# COREAON_PRM register map
Vendor: Texas Instruments
Peripheral module from a debugger description file (folder am571x).
Registers are 32-bit, access per field, reset 0x1 unless marked. A register's access mark holds for its fields unless they carry their own. Offsets are as the file gives them; lines under a group give offsets from that group; [hi:lo] are bit positions; {n}, {i} and the like mark numbered series; 'fields as' and 'values as' point back to an identical list; <NAME> marks a mode.

## COREAON_PRM
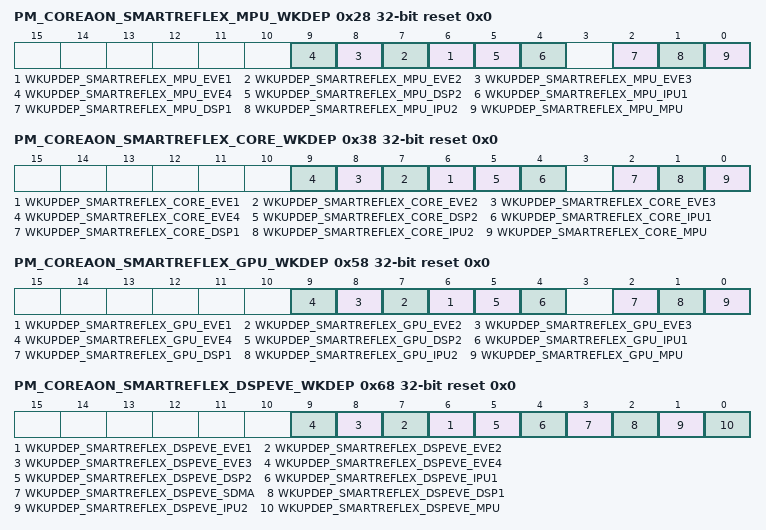
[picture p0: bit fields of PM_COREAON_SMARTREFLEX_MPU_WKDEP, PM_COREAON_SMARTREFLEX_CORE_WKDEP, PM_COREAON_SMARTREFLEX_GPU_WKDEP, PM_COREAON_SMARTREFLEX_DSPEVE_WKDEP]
0x28 PM_COREAON_SMARTREFLEX_MPU_WKDEP reset 0x0 — This register controls wakeup dependency based on SMARTREFLEX_MPU service requests.
  [all] fields
    0=DISABLED (Dependency is disabled); 1=ENABLED (Dependency is enabled)
  [n+5] WKUPDEP_SMARTREFLEX_MPU_EVE{n} rw (n=1..4) — Wakeup dependency from SMARTREFLEX_MPU module (SWakeup signal) towards EVE{n} + L3_MAIN1 + L4PER1 + L4PER2 + L4PER3 domains
  [5] WKUPDEP_SMARTREFLEX_MPU_DSP2 rw — Wakeup dependency from SMARTREFLEX_MPU module (SWakeup signal) towards DSP2 + L3_MAIN1 + L4PER1 + L4PER2 + L4PER3 domains
  [4] WKUPDEP_SMARTREFLEX_MPU_IPU1 rw — Wakeup dependency from SMARTREFLEX_MPU module (SWakeup signal) towards IPU1 + L3_MAIN1 + L4PER1 + L4PER2 + L4PER3 domains
  [2] WKUPDEP_SMARTREFLEX_MPU_DSP1 rw — Wakeup dependency from SMARTREFLEX_MPU module (SWakeup signal) towards DSP + L3MAIN1 + L4PER1 + L4PER2 + L4PER3 domains
  [1] WKUPDEP_SMARTREFLEX_MPU_IPU2 rw — Wakeup dependency from SMARTREFLEX_MPU module (SWakeup signal) towards IPU2 + L3_MAIN1 + L4PER1 + L4PER2 + L4PER3 domains
  [0] WKUPDEP_SMARTREFLEX_MPU_MPU rw — Wakeup dependency from SMARTREFLEX_MPU module (SWakeup signal) towards MPU + L3_MAIN1 + L4PER1 + L4PER2 + L4PER3 domains
0x2C RM_COREAON_SMARTREFLEX_MPU_CONTEXT — This register contains dedicated SMARTREFLEX_MPU context statuses. [warm reset insensitive]
  [0] LOSTCONTEXT_DFF rw — Specify if DFF-based context has been lost due to a previous power transition or other reset source. (set upon assertion of COREAON_RST signal)
    0=MAINTAINED (Context has been maintained); 1=LOST (Context has been lost)
0x38 PM_COREAON_SMARTREFLEX_CORE_WKDEP reset 0x0 — This register controls wakeup dependency based on SMARTREFLEX_CORE service requests.
  [all] fields
    values as the fields of PM_COREAON_SMARTREFLEX_MPU_WKDEP
  [n+5] WKUPDEP_SMARTREFLEX_CORE_EVE{n} rw (n=1..4) — Wakeup dependency from SMARTREFLEX_CORE module (SWakeup signal) towards EVE{n} + L3_MAIN1 + L4PER1 + L4PER2 + L4PER3 domains
  [5] WKUPDEP_SMARTREFLEX_CORE_DSP2 rw — Wakeup dependency from SMARTREFLEX_CORE module (SWakeup signal) towards DSP2 + L3_MAIN1 + L4PER1 + L4PER2 + L4PER3 domains
  [4] WKUPDEP_SMARTREFLEX_CORE_IPU1 rw — Wakeup dependency from SMARTREFLEX_CORE module (SWakeup signal) towards IPU1 + L3_MAIN1 + L4PER1 + L4PER2 + L4PER3 domains
  [2] WKUPDEP_SMARTREFLEX_CORE_DSP1 rw — Wakeup dependency from SMARTREFLEX_CORE module (SWakeup signal) towards DSP + L3MAIN1 + L4PER1 + L4PER2 + L4PER3 domains
  [1] WKUPDEP_SMARTREFLEX_CORE_IPU2 rw — Wakeup dependency from SMARTREFLEX_CORE module (SWakeup signal) towards IPU2 + L3_MAIN1 + L4PER1 + L4PER2 + L4PER3 domains
  [0] WKUPDEP_SMARTREFLEX_CORE_MPU rw — Wakeup dependency from SMARTREFLEX_CORE module (SWakeup signal) towards MPU + L3_MAIN1 + L4PER1 + L4PER2 + L4PER3 domains
0x3C RM_COREAON_SMARTREFLEX_CORE_CONTEXT — This register contains dedicated SMARTREFLEX_CORE context statuses. [warm reset insensitive]
  fields as RM_COREAON_SMARTREFLEX_MPU_CONTEXT
0x58 PM_COREAON_SMARTREFLEX_GPU_WKDEP reset 0x0 — This register controls wakeup dependency based on SMARTREFLEX_GPU service requests.
  [all] fields
    values as the fields of PM_COREAON_SMARTREFLEX_MPU_WKDEP
  [n+5] WKUPDEP_SMARTREFLEX_GPU_EVE{n} rw (n=1..4) — Wakeup dependency from SMARTREFLEX_GPU module (SWakeup signal) towards EVE{n} + L3_MAIN1 + L4PER1 + L4PER2 + L4PER3 domains
  [5] WKUPDEP_SMARTREFLEX_GPU_DSP2 rw — Wakeup dependency from SMARTREFLEX_GPU module (SWakeup signal) towards DSP2 + L3_MAIN1 + L4PER1 + L4PER2 + L4PER3 domains
  [4] WKUPDEP_SMARTREFLEX_GPU_IPU1 rw — Wakeup dependency from SMARTREFLEX_GPU module (SWakeup signal) towards IPU1 + L3_MAIN1 + L4PER1 + L4PER2 + L4PER3 domains
  [2] WKUPDEP_SMARTREFLEX_GPU_DSP1 rw — Wakeup dependency from SMARTREFLEX_GPU module (SWakeup signal) towards DSP + L3MAIN1 + L4PER1 + L4PER2 + L4PER3 domains
  [1] WKUPDEP_SMARTREFLEX_GPU_IPU2 rw — Wakeup dependency from SMARTREFLEX_GPU module (SWakeup signal) towards IPU2 + L3_MAIN1 + L4PER1 + L4PER2 + L4PER3 domains
  [0] WKUPDEP_SMARTREFLEX_GPU_MPU rw — Wakeup dependency from SMARTREFLEX_GPU module (SWakeup signal) towards MPU + L3_MAIN1 + L4PER1 + L4PER2 + L4PER3 domains
0x5C RM_COREAON_SMARTREFLEX_GPU_CONTEXT — This register contains dedicated SMARTREFLEX_GPU context statuses. [warm reset insensitive]
  fields as RM_COREAON_SMARTREFLEX_MPU_CONTEXT
0x68 PM_COREAON_SMARTREFLEX_DSPEVE_WKDEP reset 0x0 — This register controls wakeup dependency based on SMARTREFLEX_DSPEVE service requests.
  [all] fields
    values as the fields of PM_COREAON_SMARTREFLEX_MPU_WKDEP
  [n+5] WKUPDEP_SMARTREFLEX_DSPEVE_EVE{n} rw (n=1..4) — Wakeup dependency from SMARTREFLEX_DSPEVE module (SWakeup signal) towards EVE{n} + L3_MAIN1 + L4PER1 + L4PER2 + L4PER3 domains
  [5] WKUPDEP_SMARTREFLEX_DSPEVE_DSP2 rw — Wakeup dependency from SMARTREFLEX_DSPEVE module (SWakeup signal) towards DSP2 + L3_MAIN1 + L4PER1 + L4PER2 + L4PER3 domains
  [4] WKUPDEP_SMARTREFLEX_DSPEVE_IPU1 rw — Wakeup dependency from SMARTREFLEX_DSPEVE module (SWakeup signal) towards IPU1 + L3_MAIN1 + L4PER1 + L4PER2 + L4PER3 domains
  [3] WKUPDEP_SMARTREFLEX_DSPEVE_SDMA rw — Wakeup dependency from SMARTREFLEX_DSPEVE module (SWakeup signal) towards SDMA + L3MAIN1 + L4PER1 + L4PER2 + L4PER3 domains
  [2] WKUPDEP_SMARTREFLEX_DSPEVE_DSP1 rw — Wakeup dependency from SMARTREFLEX_GPU module (SWakeup signal) towards DSP + L3MAIN1 + L4PER1 + L4PER2 + L4PER3 domains
  [1] WKUPDEP_SMARTREFLEX_DSPEVE_IPU2 rw — Wakeup dependency from SMARTREFLEX_DSPEVE module (SWakeup signal) towards IPU2 + L3_MAIN1 + L4PER1 + L4PER2 + L4PER3 domains
  [0] WKUPDEP_SMARTREFLEX_DSPEVE_MPU rw — Wakeup dependency from SMARTREFLEX_DSPEVE module (SWakeup signal) towards MPU + L3_MAIN1 + L4PER1 + L4PER2 + L4PER3 domains
0x6C RM_COREAON_SMARTREFLEX_DSPEVE_CONTEXT — This register contains dedicated SMARTREFLEX_DSPEVE context statuses. [warm reset insensitive]
  fields as RM_COREAON_SMARTREFLEX_MPU_CONTEXT
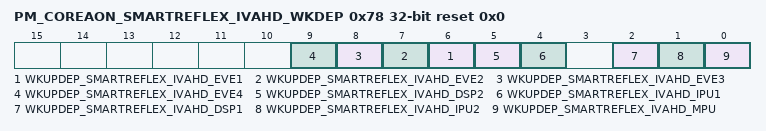
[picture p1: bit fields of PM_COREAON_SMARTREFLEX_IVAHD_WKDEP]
0x78 PM_COREAON_SMARTREFLEX_IVAHD_WKDEP reset 0x0 — This register controls wakeup dependency based on SMARTREFLEX_IVAHD service requests.
  [all] fields
    values as the fields of PM_COREAON_SMARTREFLEX_MPU_WKDEP
  [n+5] WKUPDEP_SMARTREFLEX_IVAHD_EVE{n} rw (n=1..4) — Wakeup dependency from SMARTREFLEX_IVAHD module (SWakeup signal) towards EVE{n} + L3_MAIN1 + L4PER1 + L4PER2 + L4PER3 domains
  [5] WKUPDEP_SMARTREFLEX_IVAHD_DSP2 rw — Wakeup dependency from SMARTREFLEX_IVAHD module (SWakeup signal) towards DSP2 + L3_MAIN1 + L4PER1 + L4PER2 + L4PER3 domains
  [4] WKUPDEP_SMARTREFLEX_IVAHD_IPU1 rw — Wakeup dependency from SMARTREFLEX_IVAHD module (SWakeup signal) towards IPU1 + L3_MAIN1 + L4PER1 + L4PER2 + L4PER3 domains
  [2] WKUPDEP_SMARTREFLEX_IVAHD_DSP1 rw — Wakeup dependency from SMARTREFLEX_IVAHD module (SWakeup signal) towards DSP + L3MAIN1 + L4PER1 + L4PER2 + L4PER3 domains
  [1] WKUPDEP_SMARTREFLEX_IVAHD_IPU2 rw — Wakeup dependency from SMARTREFLEX_IVAHD module (SWakeup signal) towards IPU2 + L3_MAIN1 + L4PER1 + L4PER2 + L4PER3 domains
  [0] WKUPDEP_SMARTREFLEX_IVAHD_MPU rw — Wakeup dependency from SMARTREFLEX_IVAHD module (SWakeup signal) towards MPU + L3_MAIN1 + L4PER1 + L4PER2 + L4PER3 domains
0x7C RM_COREAON_SMARTREFLEX_IVAHD_CONTEXT — This register contains dedicated SMARTREFLEX_IVA context statuses. [warm reset insensitive]
  fields as RM_COREAON_SMARTREFLEX_MPU_CONTEXT
0xAC RM_COREAON_DUMMY_MODULE1_CONTEXT — This register contains dedicated DUMMY MODULE1 context statuses. [warm reset insensitive]
  fields as RM_COREAON_SMARTREFLEX_MPU_CONTEXT
0xBC RM_COREAON_DUMMY_MODULE2_CONTEXT — This register contains dedicated DUMMY MODULE2 context statuses. [warm reset insensitive]
  fields as RM_COREAON_SMARTREFLEX_MPU_CONTEXT
0xCC RM_COREAON_DUMMY_MODULE3_CONTEXT — This register contains DUMMY MODULE USBSTUB context statuses. [warm reset insensitive]
  fields as RM_COREAON_SMARTREFLEX_MPU_CONTEXT
0xDC RM_COREAON_DUMMY_MODULE4_CONTEXT — This register contains dedicated DUMMY MODULE context statuses. [warm reset insensitive]
  fields as RM_COREAON_SMARTREFLEX_MPU_CONTEXT
